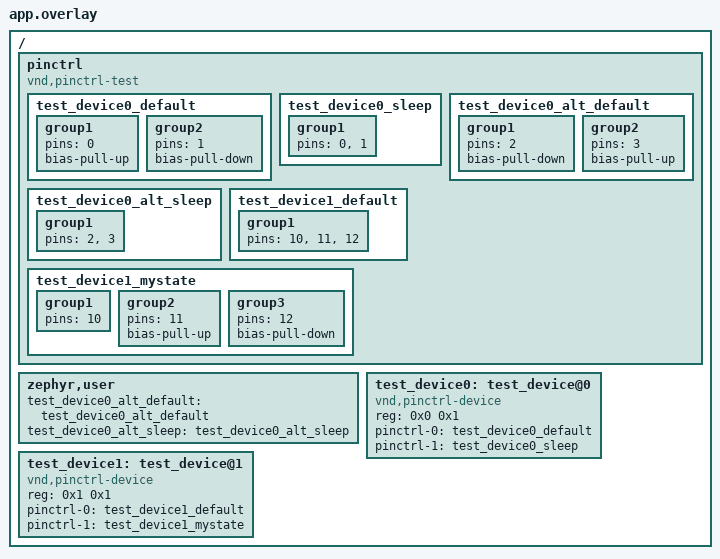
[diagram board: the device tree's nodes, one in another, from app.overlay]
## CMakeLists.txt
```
# Copyright (c) 2021 Nordic Semiconductor ASA
# SPDX-License-Identifier: Apache-2.0

cmake_minimum_required(VERSION 3.28.0)
find_package(Zephyr REQUIRED HINTS $ENV{ZEPHYR_BASE})

project(pinctrl_api)

zephyr_include_directories(src)
zephyr_include_directories(../common)

target_sources(app PRIVATE src/main.c ../common/test_device.c)
```

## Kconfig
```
# Copyright (c) 2021 Nordic Semiconductor ASA
# SPDX-License-Identifier: Apache-2.0

mainmenu "pinctrl API Test"

source "Kconfig.zephyr"

config PINCTRL_TEST_STORE_REG
	bool "Store register address"
	select PINCTRL_STORE_REG
	help
	  This option should be selected by unit tests that want to store the
	  register address of devices.
```

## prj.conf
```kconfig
# Copyright (c) 2021 Nordic Semiconductor ASA
# SPDX-License-Identifier: Apache-2.0

CONFIG_ZTEST=y
CONFIG_PINCTRL=y
CONFIG_PINCTRL_DYNAMIC=y
CONFIG_DEVICE_DEINIT_SUPPORT=n
```

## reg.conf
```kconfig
# Copyright (c) 2021 Nordic Semiconductor ASA
# SPDX-License-Identifier: Apache-2.0

CONFIG_PINCTRL_TEST_STORE_REG=y
```

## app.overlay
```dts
/*
 * Copyright (c) 2021 Nordic Semiconductor ASA
 *
 * SPDX-License-Identifier: Apache-2.0
 */

/ {
	pinctrl {
		compatible = "vnd,pinctrl-test";

		/* default state for device 0 */
		test_device0_default: test_device0_default {
			group1 {
				pins = <0>;
				bias-pull-up;
			};

			group2 {
				pins = <1>;
				bias-pull-down;
			};
		};

		/* sleep state for device 0 */
		test_device0_sleep: test_device0_sleep {
			group1 {
				pins = <0>, <1>;
			};
		};

		/* alternative default state for device 0 */
		test_device0_alt_default: test_device0_alt_default {
			group1 {
				pins = <2>;
				bias-pull-down;
			};

			group2 {
				pins = <3>;
				bias-pull-up;
			};
		};

		/* alternative sleep state for device 0 */
		test_device0_alt_sleep: test_device0_alt_sleep {
			group1 {
				pins = <2>, <3>;
			};
		};

		/* default state for device 1 */
		test_device1_default: test_device1_default {
			group1 {
				pins = <10>, <11>, <12>;
			};
		};

		/* custom state "mystate" for device 1 */
		test_device1_mystate: test_device1_mystate {
			group1 {
				pins = <10>;
			};

			group2 {
				pins = <11>;
				bias-pull-up;
			};

			group3 {
				pins = <12>;
				bias-pull-down;
			};
		};
	};

	zephyr,user {
		test_device0_alt_default = <&test_device0_alt_default>;
		test_device0_alt_sleep = <&test_device0_alt_sleep>;
	};

	test_device0: test_device@0 {
		compatible = "vnd,pinctrl-device";
		reg = <0x0 0x1>;
		pinctrl-0 = <&test_device0_default>;
		pinctrl-1 = <&test_device0_sleep>;
		pinctrl-names = "default", "sleep";
	};

	test_device1: test_device@1 {
		compatible = "vnd,pinctrl-device";
		reg = <0x1 0x1>;
		pinctrl-0 = <&test_device1_default>;
		pinctrl-1 = <&test_device1_mystate>;
		pinctrl-names = "default", "mystate";
	};
};
```

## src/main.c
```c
/*
 * Copyright (c) 2021 Nordic Semiconductor ASA
 *
 * SPDX-License-Identifier: Apache-2.0
 */

#include "test_device.h"

#include <zephyr/drivers/pinctrl.h>
#include <zephyr/fff.h>
#include <zephyr/ztest.h>

DEFINE_FFF_GLOBALS;

FAKE_VALUE_FUNC(int, pinctrl_configure_pins, const pinctrl_soc_pin_t *, uint8_t, uintptr_t);

/* test device 0 */
#define TEST_DEVICE0 DT_NODELABEL(test_device0)
PINCTRL_DT_DEV_CONFIG_DECLARE(TEST_DEVICE0);
static struct pinctrl_dev_config *pcfg0 = PINCTRL_DT_DEV_CONFIG_GET(TEST_DEVICE0);

/* test device 1 */
#define TEST_DEVICE1 DT_NODELABEL(test_device1)
PINCTRL_DT_DEV_CONFIG_DECLARE(TEST_DEVICE1);
static struct pinctrl_dev_config *pcfg1 = PINCTRL_DT_DEV_CONFIG_GET(TEST_DEVICE1);

/**
 * @brief Test if configuration for device 0 has been stored as expected.
 *
 * Device 0 is also used to verify that certain states are skipped
 * automatically, e.g. "sleep" if CONFIG_PM_DEVICE is not active.
 *
 * This test together with test_config_dev1 is used to verify that the whole
 * set of macros used to define and initialize pin control config from
 * Devicetree works as expected.
 */
ZTEST(pinctrl_api, test_config_dev0)
{
	const struct pinctrl_state *scfg;

	zassert_equal(pcfg0->state_cnt, 1);
#ifdef CONFIG_PINCTRL_STORE_REG
	zassert_equal(pcfg0->reg, 0);
#endif

	scfg = &pcfg0->states[0];
	zassert_equal(scfg->id, PINCTRL_STATE_DEFAULT);
	zassert_equal(TEST_GET_PIN(scfg->pins[0]), 0);
	zassert_equal(TEST_GET_PULL(scfg->pins[0]), TEST_PULL_UP);
	zassert_equal(TEST_GET_PIN(scfg->pins[1]), 1);
	zassert_equal(TEST_GET_PULL(scfg->pins[1]), TEST_PULL_DOWN);
}

/**
 * @brief Test if configuration for device 1 has been stored as expected.
 *
 * Device 1 is also used to verify that custom states can be defined.
 *
 * @see test_config_dev0()
 */
ZTEST(pinctrl_api, test_config_dev1)
{
	const struct pinctrl_state *scfg;

	zassert_equal(pcfg1->state_cnt, 2);
#ifdef CONFIG_PINCTRL_STORE_REG
	zassert_equal(pcfg1->reg, 1);
#endif

	scfg = &pcfg1->states[0];
	zassert_equal(scfg->id, PINCTRL_STATE_DEFAULT);
	zassert_equal(scfg->pin_cnt, 3);
	zassert_equal(TEST_GET_PIN(scfg->pins[0]), 10);
	zassert_equal(TEST_GET_PULL(scfg->pins[0]), TEST_PULL_DISABLE);
	zassert_equal(TEST_GET_PIN(scfg->pins[1]), 11);
	zassert_equal(TEST_GET_PULL(scfg->pins[1]), TEST_PULL_DISABLE);
	zassert_equal(TEST_GET_PIN(scfg->pins[2]), 12);
	zassert_equal(TEST_GET_PULL(scfg->pins[2]), TEST_PULL_DISABLE);

	scfg = &pcfg1->states[1];
	zassert_equal(scfg->id, PINCTRL_STATE_MYSTATE);
	zassert_equal(scfg->pin_cnt, 3);
	zassert_equal(TEST_GET_PIN(scfg->pins[0]), 10);
	zassert_equal(TEST_GET_PULL(scfg->pins[0]), TEST_PULL_DISABLE);
	zassert_equal(TEST_GET_PIN(scfg->pins[1]), 11);
	zassert_equal(TEST_GET_PULL(scfg->pins[1]), TEST_PULL_UP);
	zassert_equal(TEST_GET_PIN(scfg->pins[2]), 12);
	zassert_equal(TEST_GET_PULL(scfg->pins[2]), TEST_PULL_DOWN);
}

/**
 * @brief Test that pinctrl_lookup_state() works as expected
 */
ZTEST(pinctrl_api, test_lookup_state)
{
	int ret;
	const struct pinctrl_state *scfg;

	ret = pinctrl_lookup_state(pcfg0, PINCTRL_STATE_DEFAULT, &scfg);
	zassert_equal(ret, 0);
	zassert_equal_ptr(scfg, &pcfg0->states[0]);

	ret = pinctrl_lookup_state(pcfg0, PINCTRL_STATE_SLEEP, &scfg);
	zassert_equal(ret, -ENOENT);
}

/**
 * @brief Test that pinctrl_apply_state() works as expected.
 */
ZTEST(pinctrl_api, test_apply_state)
{
	zassert_ok(pinctrl_apply_state(pcfg0, PINCTRL_STATE_DEFAULT));
	zassert_equal(1, pinctrl_configure_pins_fake.call_count);
	zassert_equal(pcfg0->states[0].pins, pinctrl_configure_pins_fake.arg0_val);
	zassert_equal(pcfg0->states[0].pin_cnt, pinctrl_configure_pins_fake.arg1_val);
#ifdef CONFIG_PINCTRL_STORE_REG
	zassert_equal(0, pinctrl_configure_pins_fake.arg2_val);
#else
	zassert_equal(PINCTRL_REG_NONE, pinctrl_configure_pins_fake.arg2_val);
#endif
}

/**
 * @brief Test that pinctrl_apply_state() propagates backend errors.
 */
ZTEST(pinctrl_api, test_apply_state_propagates_error)
{
	int ret;

	pinctrl_configure_pins_fake.return_val = -EIO;

	ret = pinctrl_apply_state(pcfg0, PINCTRL_STATE_DEFAULT);

	zassert_equal(-EIO, ret);
	zassert_equal(1, pinctrl_configure_pins_fake.call_count);
}

/**
 * @brief Test that pinctrl_apply_state() rejects a missing state.
 *
 * Verify that -ENOENT is returned without calling pinctrl_configure_pins().
 */
ZTEST(pinctrl_api, test_apply_state_missing_state)
{
	zassert_equal(-ENOENT, pinctrl_apply_state(pcfg0, PINCTRL_STATE_MYSTATE));
	zassert_equal(0, pinctrl_configure_pins_fake.call_count);
}

/** Test device 0 alternative pins for default state */
PINCTRL_DT_STATE_PINS_DEFINE(DT_PATH(zephyr_user), test_device0_alt_default);
/** Test device 0 alternative pins for sleep state */
PINCTRL_DT_STATE_PINS_DEFINE(DT_PATH(zephyr_user), test_device0_alt_sleep);

/** Test device 0 alternative states. */
static const struct pinctrl_state test_device0_alt[] = {
	PINCTRL_DT_STATE_INIT(test_device0_alt_default, PINCTRL_STATE_DEFAULT),
};

/** Test device 0 invalid alternative states. */
static const struct pinctrl_state test_device0_alt_invalid[] = {
	PINCTRL_DT_STATE_INIT(test_device0_alt_default, PINCTRL_STATE_DEFAULT),
	/* sleep state is skipped (no CONFIG_PM_DEVICE), so it is invalid */
	PINCTRL_DT_STATE_INIT(test_device0_alt_sleep, PINCTRL_STATE_SLEEP),
};

/**
 * @brief This test checks if pinctrl_update_states() works as expected.
 */
ZTEST(pinctrl_api, test_update_states)
{
	int ret;
	const struct pinctrl_state *scfg;

	ret = pinctrl_update_states(pcfg0, test_device0_alt, ARRAY_SIZE(test_device0_alt));
	zassert_equal(ret, 0);

	scfg = &pcfg0->states[0];
	zassert_equal(TEST_GET_PIN(scfg->pins[0]), 2);
	zassert_equal(TEST_GET_PULL(scfg->pins[0]), TEST_PULL_DOWN);
	zassert_equal(TEST_GET_PIN(scfg->pins[1]), 3);
	zassert_equal(TEST_GET_PULL(scfg->pins[1]), TEST_PULL_UP);

	ret = pinctrl_update_states(pcfg0, test_device0_alt_invalid,
				    ARRAY_SIZE(test_device0_alt_invalid));
	zassert_equal(ret, -EINVAL);
}

static void pinctrl_api_before(void *f)
{
	ARG_UNUSED(f);
	RESET_FAKE(pinctrl_configure_pins);
	FFF_RESET_HISTORY();
}

ZTEST_SUITE(pinctrl_api, NULL, NULL, pinctrl_api_before, NULL, NULL);
```

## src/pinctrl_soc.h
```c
/*
 * Copyright (c) 2021 Nordic Semiconductor ASA
 *
 * SPDX-License-Identifier: Apache-2.0
 */

/**
 * @file
 * Testing specific helpers for pinctrl driver.
 */

#ifndef ZEPHYR_TESTS_DRIVERS_PINCTRL_API_SRC_PINCTRL_SOC_H_
#define ZEPHYR_TESTS_DRIVERS_PINCTRL_API_SRC_PINCTRL_SOC_H_

#include <zephyr/devicetree.h>
#include <zephyr/types.h>

/**
 * @name Test pin configuration bit field positions and masks.
 *
 * Bits 31, 30: Pull config.
 * Bits 29..0: Pin.
 *
 * @{
 */

/** Position of the pull field. */
#define TEST_PULL_POS 30U
/** Mask of the pull field. */
#define TEST_PULL_MSK 0x3U
/** Position of the pin field. */
#define TEST_PIN_POS 0U
/** Mask for the pin field. */
#define TEST_PIN_MSK 0x3FFFFFFFU

/** @} */

/**
 * @name Test pinctrl pull-up/down.
 * @{
 */

/** Pull-up disabled. */
#define TEST_PULL_DISABLE 0U
/** Pull-down enabled. */
#define TEST_PULL_DOWN 1U
/** Pull-up enabled. */
#define TEST_PULL_UP 2U

/** @} */

/**
 * @brief Utility macro to obtain pin pull configuration.
 *
 * @param pincfg Pin configuration bit field.
 */
#define TEST_GET_PULL(pincfg) (((pincfg) >> TEST_PULL_POS) & TEST_PULL_MSK)

/**
 * @brief Utility macro to obtain port and pin combination.
 *
 * @param pincfg Pin configuration bit field.
 */
#define TEST_GET_PIN(pincfg) (((pincfg) >> TEST_PIN_POS) & TEST_PIN_MSK)

/** @cond INTERNAL_HIDDEN */

/** Test pin type */
typedef uint32_t pinctrl_soc_pin_t;

/**
 * @brief Utility macro to initialize each pin.
 *
 * @param node_id Node identifier.
 * @param prop Property name.
 * @param idx Property entry index.
 */
#define Z_PINCTRL_STATE_PIN_INIT(node_id, prop, idx)			       \
	(((DT_PROP_BY_IDX(node_id, prop, idx) << TEST_PIN_POS)		       \
	  & TEST_PIN_MSK) |						       \
	 ((TEST_PULL_UP * DT_PROP(node_id, bias_pull_up))		       \
	  << TEST_PULL_POS) |						       \
	 ((TEST_PULL_DOWN * DT_PROP(node_id, bias_pull_down))		       \
	  << TEST_PULL_POS)						       \
	),

/**
 * @brief Utility macro to initialize state pins contained in a given property.
 *
 * @param node_id Node identifier.
 * @param prop Property name describing state pins.
 */
#define Z_PINCTRL_STATE_PINS_INIT(node_id, prop)			       \
	{DT_FOREACH_CHILD_VARGS(DT_PROP_BY_IDX(node_id, prop, 0),	       \
				DT_FOREACH_PROP_ELEM, pins,		       \
				Z_PINCTRL_STATE_PIN_INIT)}

/** @endcond */

#endif /* ZEPHYR_TESTS_DRIVERS_PINCTRL_API_SRC_PINCTRL_SOC_H_ */
```

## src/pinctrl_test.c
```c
/*
 * Copyright (c) 2021 Nordic Semiconductor ASA
 *
 * SPDX-License-Identifier: Apache-2.0
 */

#include <zephyr/drivers/pinctrl.h>
#include <ztest.h>

/* pinctrl test driver implemented as a mock */

int pinctrl_configure_pins(const pinctrl_soc_pin_t *pins, uint8_t pin_cnt,
			   uintptr_t reg)
{
	ztest_check_expected_data(pins, pin_cnt * sizeof(*pins));
	ztest_check_expected_value(pin_cnt);
	ztest_check_expected_value(reg);

	return 0;
}
```
